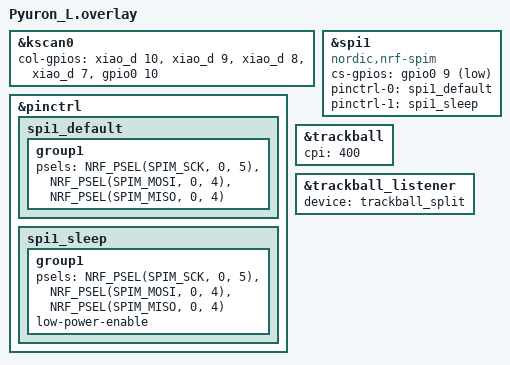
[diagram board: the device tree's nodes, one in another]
#include "Pyuron.dtsi"

// 左側のキーマトリックス設定
&kscan0 {
    col-gpios
        = <&xiao_d 10 GPIO_ACTIVE_HIGH>
        , <&xiao_d 9 GPIO_ACTIVE_HIGH> 
        , <&xiao_d 8 GPIO_ACTIVE_HIGH> 
        , <&xiao_d 7 GPIO_ACTIVE_HIGH> 
        , <&gpio0 10 GPIO_ACTIVE_HIGH>
        ;
};

// 左側のピン設定（SPI用）
&pinctrl {
    spi1_default: spi1_default {
        group1 {
            psels = <NRF_PSEL(SPIM_SCK, 0, 5)>,
                    <NRF_PSEL(SPIM_MOSI, 0, 4)>,
                    <NRF_PSEL(SPIM_MISO, 0, 4)>;
        };
    };

    spi1_sleep: spi1_sleep {
        group1 {
            psels = <NRF_PSEL(SPIM_SCK, 0, 5)>,
                    <NRF_PSEL(SPIM_MOSI, 0, 4)>,
                    <NRF_PSEL(SPIM_MISO, 0, 4)>;
            low-power-enable;
        };
    };
};

// 左側のSPI設定（トラックボール用）
&spi1 {
    status = "okay";
    compatible = "nordic,nrf-spim";
    cs-gpios = <&gpio0 9 GPIO_ACTIVE_LOW>;
    pinctrl-0 = <&spi1_default>;
    pinctrl-1 = <&spi1_sleep>;
    pinctrl-names = "default", "sleep";
};

// 左側のトラックボール設定（スクロール用）
&trackball {
    status = "okay";
    cpi = <400>;  // 左側は低感度でスクロール用
};

// 左側のトラックボール入力をスクロールとして処理
&trackball_listener {
    status = "okay";
    device = <&trackball_split>;
};
